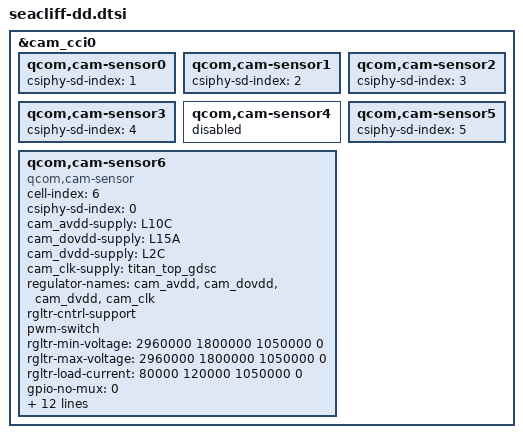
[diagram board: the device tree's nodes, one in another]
&cam_cci0 {
	qcom,cam-sensor0 {
		csiphy-sd-index = <1>;
	};

	qcom,cam-sensor1 {
		csiphy-sd-index = <2>;
	};

	qcom,cam-sensor2 {
		csiphy-sd-index = <3>;
	};

	qcom,cam-sensor3 {
		csiphy-sd-index = <4>;
	};

	/* No RGB */
	qcom,cam-sensor4 {
		status = "disabled";
	};

	qcom,cam-sensor5 {
		csiphy-sd-index = <5>;
	};

/* Instead, we have an extra FPGA with Esker Cameras */
	qcom,cam-sensor6 {
		/* CAMERA ID = 6
		 * name: Esker GT (doubledouble)
		 * QCOM CSI PHY = 0
		 * QCOM MCLK = 0
		 */
		cell-index = <6>;
		compatible = "qcom,cam-sensor";
		csiphy-sd-index = <0>;
		cam_avdd-supply = <&L10C>;
		cam_dovdd-supply = <&L15A>;
		cam_dvdd-supply = <&L2C>;
		cam_clk-supply = <&titan_top_gdsc>;
		regulator-names = "cam_avdd", "cam_dovdd", "cam_dvdd",
			"cam_clk";
		rgltr-cntrl-support;
		pwm-switch;
		rgltr-min-voltage = <2960000 1800000 1050000 0>;
		rgltr-max-voltage = <2960000 1800000 1050000 0>;
		rgltr-load-current = <80000 120000 1050000 0>;
		gpio-no-mux = <0>;
		pinctrl-names = "cam_default", "cam_suspend";
		pinctrl-0 = <&cam_sensor_mclk0_active>;
		pinctrl-1 = <&cam_sensor_mclk0_suspend>;
		gpios = <&tlmm 94 0>;
		gpio-req-tbl-num = <0>;
		gpio-req-tbl-flags = <1>;
		gpio-req-tbl-label = "CAMIF_MCLK0";
		sensor-mode = <0>;
		cci-master = <1>;
		clocks = <&clock_camcc CAM_CC_MCLK0_CLK>;
		clock-names = "cam_clk";
		clock-cntl-level = "turbo";
		clock-rates = <19200000>;
		oculus,cam-mclk-no-power-down;
	};
};
